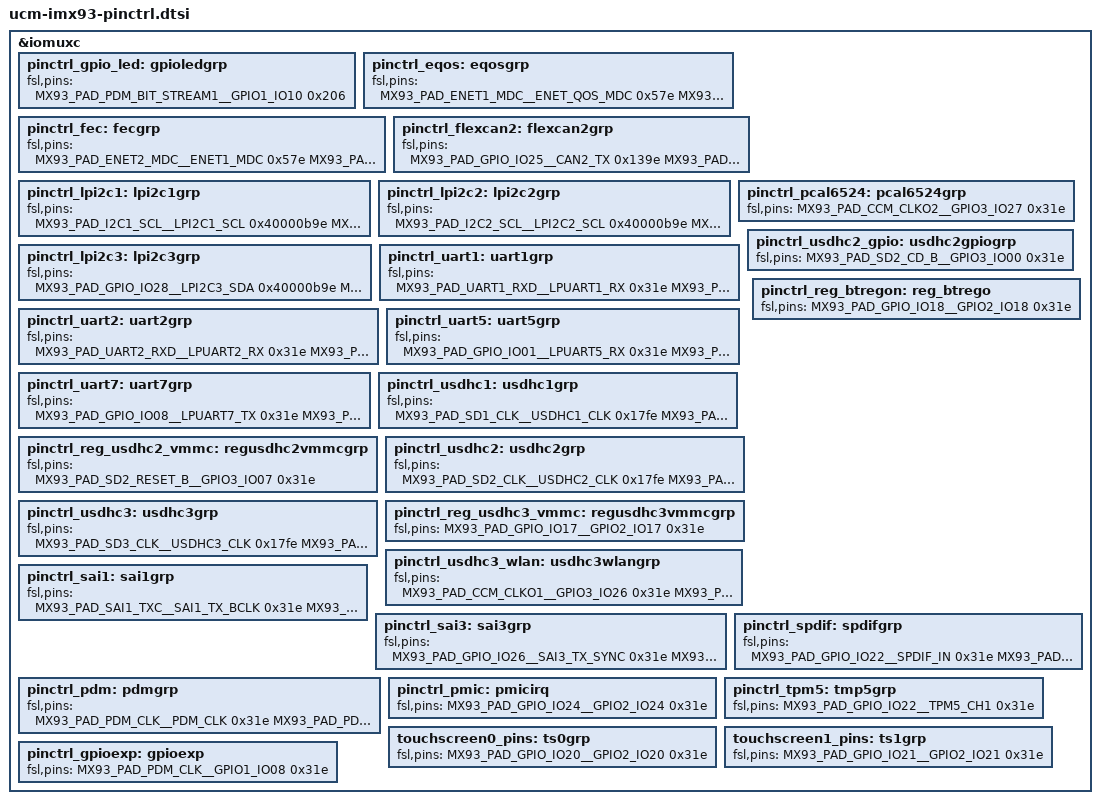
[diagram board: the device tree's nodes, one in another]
// SPDX-License-Identifier: (GPL-2.0+ OR MIT)
/*
 * Copyright 2023 Compulab
 */

&iomuxc {
	pinctrl_gpio_led: gpioledgrp {
		fsl,pins = <
			MX93_PAD_PDM_BIT_STREAM1__GPIO1_IO10	0x206
		>;
	};

	pinctrl_eqos: eqosgrp {
		fsl,pins = <
			MX93_PAD_ENET1_MDC__ENET_QOS_MDC			0x57e
			MX93_PAD_ENET1_MDIO__ENET_QOS_MDIO			0x57e
			MX93_PAD_ENET1_RD0__ENET_QOS_RGMII_RD0			0x57e
			MX93_PAD_ENET1_RD1__ENET_QOS_RGMII_RD1			0x57e
			MX93_PAD_ENET1_RD2__ENET_QOS_RGMII_RD2			0x57e
			MX93_PAD_ENET1_RD3__ENET_QOS_RGMII_RD3			0x57e
			MX93_PAD_ENET1_RXC__CCM_ENET_QOS_CLOCK_GENERATE_RX_CLK	0x5fe
			MX93_PAD_ENET1_RX_CTL__ENET_QOS_RGMII_RX_CTL		0x57e
			MX93_PAD_ENET1_TD0__ENET_QOS_RGMII_TD0			0x57e
			MX93_PAD_ENET1_TD1__ENET_QOS_RGMII_TD1			0x57e
			MX93_PAD_ENET1_TD2__ENET_QOS_RGMII_TD2			0x57e
			MX93_PAD_ENET1_TD3__ENET_QOS_RGMII_TD3			0x57e
			MX93_PAD_ENET1_TXC__CCM_ENET_QOS_CLOCK_GENERATE_TX_CLK	0x5fe
			MX93_PAD_ENET1_TX_CTL__ENET_QOS_RGMII_TX_CTL		0x57e
			/* reset phy gpio */
			MX93_PAD_GPIO_IO06__GPIO2_IO06				0x31e
		>;
	};

	pinctrl_fec: fecgrp {
		fsl,pins = <
			MX93_PAD_ENET2_MDC__ENET1_MDC			0x57e
			MX93_PAD_ENET2_MDIO__ENET1_MDIO			0x57e
			MX93_PAD_ENET2_RD0__ENET1_RGMII_RD0		0x57e
			MX93_PAD_ENET2_RD1__ENET1_RGMII_RD1		0x57e
			MX93_PAD_ENET2_RD2__ENET1_RGMII_RD2		0x57e
			MX93_PAD_ENET2_RD3__ENET1_RGMII_RD3		0x57e
			MX93_PAD_ENET2_RXC__ENET1_RGMII_RXC		0x5fe
			MX93_PAD_ENET2_RX_CTL__ENET1_RGMII_RX_CTL	0x57e
			MX93_PAD_ENET2_TD0__ENET1_RGMII_TD0		0x57e
			MX93_PAD_ENET2_TD1__ENET1_RGMII_TD1		0x57e
			MX93_PAD_ENET2_TD2__ENET1_RGMII_TD2		0x57e
			MX93_PAD_ENET2_TD3__ENET1_RGMII_TD3		0x57e
			MX93_PAD_ENET2_TXC__ENET1_RGMII_TXC		0x5fe
			MX93_PAD_ENET2_TX_CTL__ENET1_RGMII_TX_CTL	0x57e
		>;
	};

	pinctrl_flexcan2: flexcan2grp {
		fsl,pins = <
			MX93_PAD_GPIO_IO25__CAN2_TX	0x139e
			MX93_PAD_GPIO_IO27__CAN2_RX	0x139e
		>;
	};

	pinctrl_lpi2c1: lpi2c1grp {
		fsl,pins = <
			MX93_PAD_I2C1_SCL__LPI2C1_SCL			0x40000b9e
			MX93_PAD_I2C1_SDA__LPI2C1_SDA			0x40000b9e
		>;
	};

	pinctrl_lpi2c2: lpi2c2grp {
		fsl,pins = <
			MX93_PAD_I2C2_SCL__LPI2C2_SCL			0x40000b9e
			MX93_PAD_I2C2_SDA__LPI2C2_SDA			0x40000b9e
		>;
	};

	pinctrl_lpi2c3: lpi2c3grp {
		fsl,pins = <
			MX93_PAD_GPIO_IO28__LPI2C3_SDA			0x40000b9e
			MX93_PAD_GPIO_IO29__LPI2C3_SCL			0x40000b9e
		>;
	};

	pinctrl_pcal6524: pcal6524grp {
		fsl,pins = <
			MX93_PAD_CCM_CLKO2__GPIO3_IO27			0x31e
		>;
	};

	pinctrl_uart1: uart1grp {
		fsl,pins = <
			MX93_PAD_UART1_RXD__LPUART1_RX			0x31e
			MX93_PAD_UART1_TXD__LPUART1_TX			0x31e
		>;
	};

	pinctrl_uart2: uart2grp {
		fsl,pins = <
			MX93_PAD_UART2_RXD__LPUART2_RX		0x31e
			MX93_PAD_UART2_TXD__LPUART2_TX		0x31e
		>;
	};

	pinctrl_uart5: uart5grp {
		fsl,pins = <
			MX93_PAD_GPIO_IO01__LPUART5_RX		0x31e
			MX93_PAD_GPIO_IO00__LPUART5_TX		0x31e
			MX93_PAD_GPIO_IO02__LPUART5_CTS_B	0x31e
			MX93_PAD_GPIO_IO03__LPUART5_RTS_B	0x31e
			MX93_PAD_GPIO_IO18__GPIO2_IO18		0x31e
		>;
	};

	pinctrl_uart7: uart7grp {
		fsl,pins = <
			MX93_PAD_GPIO_IO08__LPUART7_TX		0x31e
			MX93_PAD_GPIO_IO09__LPUART7_RX		0x31e
		>;
	};

	pinctrl_usdhc1: usdhc1grp {
		fsl,pins = <
			MX93_PAD_SD1_CLK__USDHC1_CLK		0x17fe
			MX93_PAD_SD1_CMD__USDHC1_CMD		0x13fe
			MX93_PAD_SD1_DATA0__USDHC1_DATA0	0x13fe
			MX93_PAD_SD1_DATA1__USDHC1_DATA1	0x13fe
			MX93_PAD_SD1_DATA2__USDHC1_DATA2	0x13fe
			MX93_PAD_SD1_DATA3__USDHC1_DATA3	0x13fe
			MX93_PAD_SD1_DATA4__USDHC1_DATA4	0x13fe
			MX93_PAD_SD1_DATA5__USDHC1_DATA5	0x13fe
			MX93_PAD_SD1_DATA6__USDHC1_DATA6	0x13fe
			MX93_PAD_SD1_DATA7__USDHC1_DATA7	0x13fe
			MX93_PAD_SD1_STROBE__USDHC1_STROBE	0x17fe
		>;
	};

	pinctrl_reg_usdhc2_vmmc: regusdhc2vmmcgrp {
		fsl,pins = <
			MX93_PAD_SD2_RESET_B__GPIO3_IO07	0x31e
		>;
	};

	pinctrl_usdhc2_gpio: usdhc2gpiogrp {
		fsl,pins = <
			MX93_PAD_SD2_CD_B__GPIO3_IO00		0x31e
		>;
	};

	pinctrl_usdhc2: usdhc2grp {
		fsl,pins = <
			MX93_PAD_SD2_CLK__USDHC2_CLK		0x17fe
			MX93_PAD_SD2_CMD__USDHC2_CMD		0x13fe
			MX93_PAD_SD2_DATA0__USDHC2_DATA0	0x13fe
			MX93_PAD_SD2_DATA1__USDHC2_DATA1	0x13fe
			MX93_PAD_SD2_DATA2__USDHC2_DATA2	0x13fe
			MX93_PAD_SD2_DATA3__USDHC2_DATA3	0x13fe
			MX93_PAD_SD2_VSELECT__USDHC2_VSELECT	0x51e
		>;
	};

	pinctrl_usdhc3: usdhc3grp {
		fsl,pins = <
			MX93_PAD_SD3_CLK__USDHC3_CLK			0x17fe
			MX93_PAD_SD3_CMD__USDHC3_CMD			0x13fe
			MX93_PAD_SD3_DATA0__USDHC3_DATA0		0x13fe
			MX93_PAD_SD3_DATA1__USDHC3_DATA1        	0x13fe
			MX93_PAD_SD3_DATA2__USDHC3_DATA2        	0x13fe
			MX93_PAD_SD3_DATA3__USDHC3_DATA3        	0x13fe
		>;
	};

	pinctrl_reg_usdhc3_vmmc: regusdhc3vmmcgrp {
		fsl,pins = <
			MX93_PAD_GPIO_IO17__GPIO2_IO17			0x31e
		>;
	};

	pinctrl_reg_btregon: reg_btrego {
		fsl,pins = <
			MX93_PAD_GPIO_IO18__GPIO2_IO18			0x31e
		>;
	};

	pinctrl_usdhc3_wlan: usdhc3wlangrp {
		fsl,pins = <
			MX93_PAD_CCM_CLKO1__GPIO3_IO26			0x31e
			MX93_PAD_GPIO_IO07__GPIO2_IO07			0x31e
			/*MX93_PAD_GPIO_IO17__GPIO2_IO17			0x31e*/
		>;
	};

	pinctrl_sai1: sai1grp {
		fsl,pins = <
			MX93_PAD_SAI1_TXC__SAI1_TX_BCLK			0x31e
			MX93_PAD_SAI1_TXFS__SAI1_TX_SYNC		0x31e
			MX93_PAD_SAI1_TXD0__SAI1_TX_DATA00		0x31e
			MX93_PAD_SAI1_RXD0__SAI1_RX_DATA00		0x31e
		>;
	};

	pinctrl_sai3: sai3grp {
		fsl,pins = <
			MX93_PAD_GPIO_IO26__SAI3_TX_SYNC		0x31e
			MX93_PAD_GPIO_IO16__SAI3_TX_BCLK		0x31e
			/*MX93_PAD_GPIO_IO17__SAI3_MCLK		0x31e*/
			MX93_PAD_GPIO_IO19__SAI3_TX_DATA00		0x31e
			MX93_PAD_GPIO_IO20__SAI3_RX_DATA00		0x31e
		>;
	};

	pinctrl_pdm: pdmgrp {
		fsl,pins = <
			MX93_PAD_PDM_CLK__PDM_CLK			0x31e
			MX93_PAD_PDM_BIT_STREAM0__PDM_BIT_STREAM00	0x31e
			MX93_PAD_PDM_BIT_STREAM1__PDM_BIT_STREAM01	0x31e
		>;
	};

	pinctrl_spdif: spdifgrp {
		fsl,pins = <
			MX93_PAD_GPIO_IO22__SPDIF_IN		0x31e
			MX93_PAD_GPIO_IO23__SPDIF_OUT		0x31e
		>;
	};

	pinctrl_pmic: pmicirq {
		fsl,pins = <
			MX93_PAD_GPIO_IO24__GPIO2_IO24		0x31e
		>;
	};

	pinctrl_tpm5: tmp5grp {
		fsl,pins = <
			MX93_PAD_GPIO_IO22__TPM5_CH1		0x31e
		>;
	};

	touchscreen0_pins: ts0grp {
		fsl,pins = <
			MX93_PAD_GPIO_IO20__GPIO2_IO20		0x31e
		>;
	};
	touchscreen1_pins: ts1grp {
		fsl,pins = <
			MX93_PAD_GPIO_IO21__GPIO2_IO21		0x31e
		>;
	};

	pinctrl_gpioexp: gpioexp {
		fsl,pins = <
			MX93_PAD_PDM_CLK__GPIO1_IO08			0x31e
		>;
	};
};
